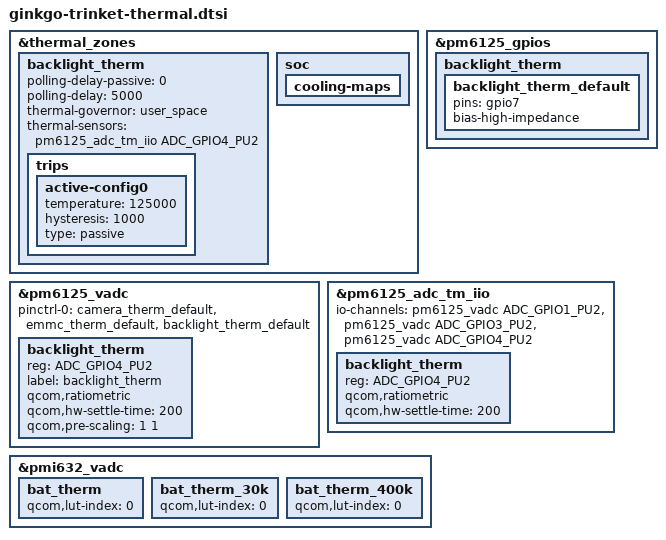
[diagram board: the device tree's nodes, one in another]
&thermal_zones {
	backlight_therm {
		polling-delay-passive = <0>;
		polling-delay = <5000>;
		thermal-governor = "user_space";
		thermal-sensors = <&pm6125_adc_tm_iio ADC_GPIO4_PU2>;
		trips {
			active-config0 {
				temperature = <125000>;
				hysteresis = <1000>;
				type = "passive";
			};
		};
	};
};

&pm6125_vadc {
	pinctrl-0 = <&camera_therm_default &emmc_therm_default &backlight_therm_default>;

	backlight_therm {
		reg = <ADC_GPIO4_PU2>;
		label = "backlight_therm";
		qcom,ratiometric;
		qcom,hw-settle-time = <200>;
		qcom,pre-scaling = <1 1>;
	};
};

&pm6125_gpios {
	backlight_therm {
		backlight_therm_default: backlight_therm_default {
			pins = "gpio7";
			bias-high-impedance;
		};
	};
};

&pm6125_adc_tm_iio {
	io-channels = <&pm6125_vadc ADC_GPIO1_PU2>,
					<&pm6125_vadc ADC_GPIO3_PU2>,
					<&pm6125_vadc ADC_GPIO4_PU2>;

	backlight_therm {
		reg = <ADC_GPIO4_PU2>;
		qcom,ratiometric;
		qcom,hw-settle-time = <200>;
	};
};

&pmi632_vadc {
	bat_therm {
		qcom,lut-index = <0>;
	};

	bat_therm_30k {
		qcom,lut-index = <0>;
	};

	bat_therm_400k {
		qcom,lut-index = <0>;
	};
};

&thermal_zones {
	soc {
		cooling-maps {
			/delete-node/ soc_cpu6;
			/delete-node/ soc_cpu7;
		};
	};
};
